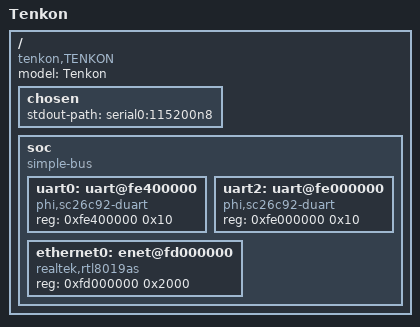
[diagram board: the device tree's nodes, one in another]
// SPDX-License-Identifier: GPL-2.0+
/*
 * Copyright (C) 2018 Angelo Dureghello <angelo@sysam.it>
 */

/dts-v1/;

/ {
	model = "Tenkon";
	compatible = "tenkon,TENKON";

	chosen {
		stdout-path = "serial0:115200n8";
	};

	soc {
		compatible = "simple-bus";
		#address-cells = <1>;
		#size-cells = <1>;

		uart0: uart@fe400000 {
			compatible = "phi,sc26c92-duart";
			reg = <0xfe400000 0x10>;
			status = "okay";
		};

		uart2: uart@fe000000 {
			compatible = "phi,sc26c92-duart";
			reg = <0xfe000000 0x10>;
			status = "okay";
		};

		ethernet0: enet@fd000000 {
			compatible = "realtek,rtl8019as";
			reg = <0xfd000000 0x2000>;
		};

    };
};

&uart0 {
	bootph-all;
	status = "okay";
};

